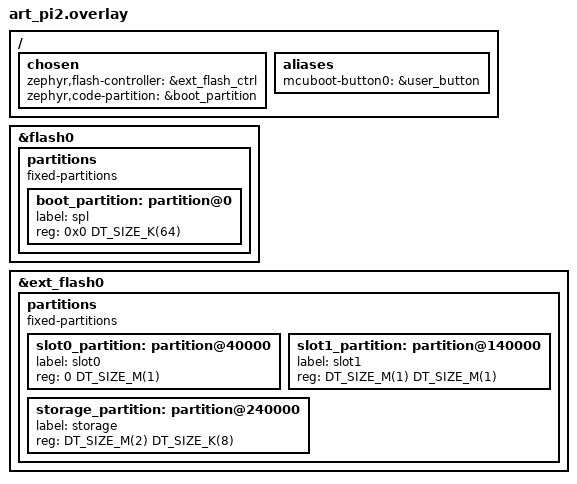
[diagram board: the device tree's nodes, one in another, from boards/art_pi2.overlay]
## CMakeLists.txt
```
# SPDX-License-Identifier: Apache-2.0

cmake_minimum_required(VERSION 3.20.0)

find_package(Zephyr REQUIRED HINTS $ENV{ZEPHYR_BASE})
project(bootloader)

target_sources(app PRIVATE
    src/main.c
    src/flash_helper.c
    ../common/ymodem.c
    src/menu.c
    ../common/firmware_loader.c
)

zephyr_include_directories(app PRIVATE_HEADER ../common)
```

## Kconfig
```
# SPDX-License-Identifier: Apache-2.0

source "Kconfig.zephyr"

config SPL_DIRECT_FLASH_WRITE
	bool "Direct Flash Write Mode (bypass RAM buffer)"
	default n
	help
	  If enabled, YModem received data is written directly to Flash
	  without using an intermediate RAM buffer. This saves RAM but
	  requires the target Flash region to be erased before reception.

	  If disabled (default), data is first received into a heap-allocated
	  RAM buffer, verified, then written to Flash.
```

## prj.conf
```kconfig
# SPDX-License-Identifier: Apache-2.0

# ========================================
# SPL (Stage 1) - 最小化配置
# ========================================

# 堆栈和堆内存配置
CONFIG_MAIN_STACK_SIZE=4096
CONFIG_HEAP_MEM_POOL_SIZE=393216

# 最小化 libc
CONFIG_MINIMAL_LIBC=y
CONFIG_STDOUT_CONSOLE=y

# 串口配置
CONFIG_SERIAL=y
CONFIG_UART_CONSOLE=y
CONFIG_UART_INTERRUPT_DRIVEN=n

# GPIO 配置
CONFIG_GPIO=y

# 内部 Flash 配置
CONFIG_FLASH=y
CONFIG_FLASH_PAGE_LAYOUT=y

# 关闭日志系统
# CONFIG_LOG is not set

# 关闭 Shell
# CONFIG_SHELL is not set

# 启动配置
CONFIG_BOOT_DELAY=0

CONFIG_INPUT=y
CONFIG_INPUT_MODE_SYNCHRONOUS=y

# CRC 支持（用于固件头校验）
CONFIG_CRC=y
CONFIG_CRC32_IEEE=y

# 关断其他不需要的功能
CONFIG_REBOOT=y

# 直接写入 Flash 模式（通过 Kconfig 启用）
# 启用后 YModem 数据不再经过 RAM 缓冲，直接写入 Flash
# 可节省 ~256KB 堆内存（TPL 场景），但要求 Flash 先擦除后写入
CONFIG_SPL_DIRECT_FLASH_WRITE=y
# CONFIG_USB_CDC_ACM=y
```

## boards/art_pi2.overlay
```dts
/ {
    chosen {
        zephyr,flash-controller = &ext_flash_ctrl;
        zephyr,code-partition = &boot_partition;
    };

    aliases {
        mcuboot-button0 = &user_button;
    };
};

&flash0 {
    partitions {
        compatible = "fixed-partitions";
        #address-cells = <1>;
        #size-cells = <1>;

        boot_partition: partition@0 {
            label = "spl";
            reg = <0x0 DT_SIZE_K(64)>;
        };
    };
};

&ext_flash0 {
    partitions {
        compatible = "fixed-partitions";
        #address-cells = <1>;
        #size-cells = <1>;

        /* 删除基础设备树中的 storage_partition */
        /delete-node/ partition@0;

        slot0_partition: partition@40000 {
            label = "slot0";
            reg = <0 DT_SIZE_M(1)>;
        };

        slot1_partition: partition@140000 {
            label = "slot1";
            reg = <DT_SIZE_M(1) DT_SIZE_M(1)>;
        };

        storage_partition: partition@240000 {
            label = "storage";
            reg = <DT_SIZE_M(2) DT_SIZE_K(8)>;
        };
    };
};
```

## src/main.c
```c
/*
 * Copyright (c) 2024
 *
 * SPDX-License-Identifier: Apache-2.0
 */

#include <string.h>
#include <zephyr/device.h>
#include <zephyr/drivers/gpio.h>
#include <zephyr/drivers/uart.h>
#include <zephyr/kernel.h>
#include <zephyr/logging/log.h>
#include <zephyr/sys/crc.h>
#include <zephyr/sys/reboot.h>

#include "firmware_loader.h"
#include "flash_helper.h"
#include "ymodem.h"

LOG_MODULE_DECLARE(spl, CONFIG_LOG_DEFAULT_LEVEL);

#define RED_LED_NODE DT_NODELABEL(red_led)
#define BLUE_LED_NODE DT_NODELABEL(blue_led)
static const struct gpio_dt_spec red_led =
    GPIO_DT_SPEC_GET_OR(RED_LED_NODE, gpios, {0});
static const struct gpio_dt_spec blue_led =
    GPIO_DT_SPEC_GET_OR(BLUE_LED_NODE, gpios, {0});
static const struct gpio_dt_spec btn0 =
    GPIO_DT_SPEC_GET(DT_ALIAS(mcuboot_button0), gpios);

struct spl_write_ctx {
  bool update_spl;
  uint32_t flash_addr;
#if !defined(CONFIG_SPL_DIRECT_FLASH_WRITE)
  uint8_t* ram_buf;
#endif
};

static void spl_init(void);
static void spl_led_init(void);
static void spl_led_set(bool red_on, bool blue_on);
static void spl_jump_to_tpl(void);
static void spl_jump_to_address(uint32_t addr);
static int spl_update_mode(bool update_spl);

int main(void) {
  int value;

  spl_init();
  gpio_pin_configure_dt(&btn0, GPIO_INPUT);

  value = gpio_pin_get_dt(&btn0);

  if (value) {
    LOG_INF("upgrading TPL");
    spl_update_mode(false);
    k_sleep(K_MSEC(1000));
    sys_reboot(SYS_REBOOT_COLD);
  }

  LOG_DBG("Checking TPL...\n");

  {
    struct firmware_header tpl_header;
    int rc;

    rc = firmware_verify_from_flash(EXT_FLASH_TPL_ADDR, &tpl_header,
                                    FW_MAGIC_TPL, flash_external_read);

    if (rc == FW_LOADER_SUCCESS) {
      LOG_DBG("TPL found at 0x%08X\n", EXT_FLASH_TPL_ADDR);
      spl_led_set(false, true); /* 蓝灯亮 */

      LOG_DBG("Jumping to TPL...\n");
      k_sleep(K_MSEC(100));

      rc = firmware_load_and_jump(&tpl_header, EXT_FLASH_TPL_ADDR,
                             flash_external_read);

      LOG_ERR("TPL jump failed (rc=%d), entering update mode...", rc);
      spl_led_set(true, true);

      if (spl_update_mode(false) == 0) {
        LOG_INF("TPL update successful, rebooting...\n");
      } else {
        LOG_ERR("TPL update failed, rebooting...\n");
      }

      k_sleep(K_MSEC(1000));
      sys_reboot(SYS_REBOOT_COLD);
    } else {
      LOG_ERR("TPL not found or invalid! (rc=%d)\n", rc);
      LOG_DBG("Entering TPL update mode...\n");
      spl_led_set(true, true);

      if (spl_update_mode(false) == 0) {
        LOG_DBG("TPL update successful, rebooting...\n");
      } else {
        LOG_ERR("TPL update failed, rebooting...\n");
      }

      k_sleep(K_MSEC(1000));
      sys_reboot(SYS_REBOOT_COLD);
    }
  }

  return 0;
}

static const struct device* g_uart_dev;

static void spl_init(void) {
  spl_led_init();
  spl_led_set(false, false);

  flash_internal_init();
  flash_external_init();

  g_uart_dev = DEVICE_DT_GET(DT_CHOSEN(zephyr_console));
  if (!device_is_ready(g_uart_dev)) {
    LOG_ERR("UART device not ready");
    while (1) {
    }
  }

  LOG_INF("SPL initialized");
}

static void spl_led_init(void) {
  if (device_is_ready(red_led.port)) {
    gpio_pin_configure_dt(&red_led, GPIO_OUTPUT);
    gpio_pin_set_dt(&red_led, 0);
  }

  if (device_is_ready(blue_led.port)) {
    gpio_pin_configure_dt(&blue_led, GPIO_OUTPUT);
    gpio_pin_set_dt(&blue_led, 0);
  }
}

static void spl_led_set(bool red_on, bool blue_on) {
  if (device_is_ready(red_led.port)) {
    gpio_pin_set_dt(&red_led, red_on ? 1 : 0);
  }

  if (device_is_ready(blue_led.port)) {
    gpio_pin_set_dt(&blue_led, blue_on ? 1 : 0);
  }
}

static int spl_block_write(uint32_t addr, const uint8_t* data, size_t len,
                           uint32_t total, int file_size, void* priv) {
  struct spl_write_ctx* ctx = (struct spl_write_ctx*)priv;

#if defined(CONFIG_SPL_DIRECT_FLASH_WRITE)
  if (ctx->update_spl) {
    return flash_internal_write(ctx->flash_addr + total - len, data, len);
  } else {
    return flash_external_write(ctx->flash_addr + total - len, data, len);
  }
#else
  memcpy(ctx->ram_buf + total - len, data, len);
  return 0;
#endif
}

static int spl_update_mode(bool update_spl) {
  struct ymodem_config config;
  struct spl_write_ctx wctx;
  struct firmware_header fw_header;
  uint32_t flash_addr;
  uint32_t max_size;
  int rc;

  if (update_spl) {
    flash_addr = FLASH_BASE_ADDR;
    max_size = SPL_FLASH_SIZE;
    LOG_INF("Send SPL firmware via YModem (max %d KB)...", max_size / 1024);
  } else {
    flash_addr = EXT_FLASH_TPL_ADDR;
    max_size = EXT_FLASH_TPL_SIZE;
    LOG_INF("Send TPL firmware via YModem (max %d KB)...", max_size / 1024);
  }

#if defined(CONFIG_SPL_DIRECT_FLASH_WRITE)
  LOG_DBG("Erasing Flash at 0x%08X (%u bytes)...", flash_addr, max_size);
  if (update_spl) {
    rc = flash_internal_erase(flash_addr, max_size);
  } else {
    rc = flash_external_erase(flash_addr, max_size);
  }
  if (rc != 0) {
    LOG_ERR("Flash erase failed (rc=%d)", rc);
    return -1;
  }
  LOG_DBG("Flash erase complete\n");

  wctx.update_spl = update_spl;
  wctx.flash_addr = flash_addr;

  config.dev = g_uart_dev;
  config.flash_addr = flash_addr;
  config.max_size = max_size;
  config.block_write_cb = spl_block_write;
  config.priv = &wctx;

  rc = ymodem_recv(&config);
  if (rc < 0) {
    LOG_ERR("YModem receive failed (%d)", rc);
    return -1;
  }
  LOG_DBG("Received %u bytes\n", rc);

  if (update_spl) {
    rc = flash_internal_read(flash_addr, (uint8_t*)&fw_header,
                             sizeof(fw_header));
  } else {
    rc = flash_external_read(flash_addr, (uint8_t*)&fw_header,
                             sizeof(fw_header));
  }
  if (rc != 0) {
    LOG_ERR("Failed to read firmware header from Flash (rc=%d)", rc);
    return -1;
  }

  rc = firmware_header_verify(&fw_header,
                              update_spl ? FW_MAGIC_SPL : FW_MAGIC_TPL);
  if (rc != FW_LOADER_SUCCESS) {
    LOG_ERR("Firmware header verification failed (rc=%d)", rc);
    return -1;
  }
  LOG_INF("Firmware header verified OK");

  {
    uint32_t payload_size = fw_header.firmware_size - FIRMWARE_HEADER_SIZE;

    if (payload_size > 0 && payload_size <= max_size) {
      uint32_t calc_crc = 0xFFFFFFFF;
      uint32_t offset = FIRMWARE_HEADER_SIZE;
      uint32_t remaining = payload_size;
      uint8_t chunk_buf[256];

      while (remaining > 0) {
        uint32_t chunk =
            (remaining > sizeof(chunk_buf)) ? sizeof(chunk_buf) : remaining;

        if (update_spl) {
          rc = flash_internal_read(flash_addr + offset, chunk_buf, chunk);
        } else {
          rc = flash_external_read(flash_addr + offset, chunk_buf, chunk);
        }
        if (rc != 0) {
          LOG_ERR("Failed to read payload from Flash at "
                  "offset 0x%X (rc=%d)",
                  offset, rc);
          return -1;
        }
        calc_crc = crc32_ieee_update(calc_crc, chunk_buf, chunk);
        offset += chunk;
        remaining -= chunk;
      }

      calc_crc ^= 0xFFFFFFFF;

      if (calc_crc == fw_header.checksum) {
        LOG_INF("Firmware checksum verified OK (0x%08X)", fw_header.checksum);
      } else {
        LOG_ERR("Firmware checksum verification failed "
                "(calc 0x%08X, stored 0x%08X)",
                calc_crc, fw_header.checksum);
      }
      LOG_INF("Firmware verified successfully (%u bytes payload)",
              payload_size);
    }
  }

#else
  uint8_t* ram_buf = k_malloc(max_size);
  if (!ram_buf) {
    LOG_ERR("RAM buffer allocation failed");
    return -1;
  }
  LOG_INF("Using RAM buffer at 0x%08X for firmware reception\n",
          (uint32_t)ram_buf);
  memset(ram_buf, 0, max_size);

  wctx.update_spl = update_spl;
  wctx.flash_addr = flash_addr;
  wctx.ram_buf = ram_buf;

  config.dev = g_uart_dev;
  config.flash_addr = (uint32_t)ram_buf;
  config.max_size = max_size;
  config.block_write_cb = spl_block_write;
  config.priv = &wctx;

  rc = ymodem_recv(&config);
  if (rc < 0) {
    LOG_ERR("YModem receive failed (%d)", rc);
    k_free(ram_buf);
    return -1;
  }
  LOG_DBG("Received %u bytes\n", rc);

  {
    const struct firmware_header* fw_header;
    int vrc;

    fw_header = (const struct firmware_header*)ram_buf;
    vrc = firmware_header_verify(fw_header,
                                 update_spl ? FW_MAGIC_SPL : FW_MAGIC_TPL);
    if (vrc != FW_LOADER_SUCCESS) {
      LOG_ERR("Firmware header verification failed (rc=%d)", vrc);
      k_free(ram_buf);
      return -1;
    }
    LOG_INF("Firmware header verified OK");

    {
      uint32_t payload_size = fw_header->firmware_size - FIRMWARE_HEADER_SIZE;
      const uint8_t* payload = (const uint8_t*)fw_header + FIRMWARE_HEADER_SIZE;

      if (payload_size > 0 && payload_size <= max_size) {
        vrc = firmware_verify_checksum(fw_header, payload);
        if (vrc == FW_LOADER_SUCCESS) {
          LOG_INF("Firmware checksum verified OK (0x%08X)",
                  fw_header->checksum);
        } else {
          LOG_ERR("Warning: Firmware checksum verification "
                  "failed (rc=%d)",
                  vrc);
        }
        LOG_INF("Firmware verified successfully (%u bytes payload)",
                payload_size);
      }
    }
  }

  {
    uint32_t write_size = (uint32_t)rc;

    LOG_DBG("Writing %u bytes to Flash at 0x%08X...", write_size, flash_addr);

    if (update_spl) {
      rc = flash_internal_erase(flash_addr, write_size);
    } else {
      rc = flash_external_erase(flash_addr, write_size);
    }
    if (rc != 0) {
      LOG_ERR("Flash erase failed (rc=%d)", rc);
      k_free(ram_buf);
      return -1;
    }

    {
      uint32_t offset = 0;
      const uint32_t chunk_size = 256;

      while (offset < write_size) {
        uint32_t chunk = (write_size - offset > chunk_size)
                             ? chunk_size
                             : (write_size - offset);

        if (update_spl) {
          rc = flash_internal_write(flash_addr + offset, ram_buf + offset,
                                    chunk);
        } else {
          rc = flash_external_write(flash_addr + offset, ram_buf + offset,
                                    chunk);
        }
        if (rc != 0) {
          LOG_ERR("Flash write failed at offset 0x%X (rc=%d)", offset, rc);
          k_free(ram_buf);
          return -1;
        }
        offset += chunk;
      }
    }
    LOG_DBG("Flash write complete\n");
    k_free(ram_buf);
  }
#endif

  return 0;
}

static void spl_jump_to_tpl(void) { spl_jump_to_address(EXT_FLASH_TPL_ADDR); }

static void spl_jump_to_address(uint32_t addr) {
  uint32_t* vector_table = (uint32_t*)addr;
  uint32_t stack_ptr;
  uint32_t reset_handler;
  void (*jump_to_app)(void);

  __disable_irq();

  SysTick->CTRL = 0;
  SysTick->VAL = 0;

  SCB->VTOR = addr;

  stack_ptr = vector_table[0];
  reset_handler = vector_table[1];

  if (!((stack_ptr >= 0x20000000 && stack_ptr <= 0x20050000) ||
        (stack_ptr >= 0x24000000 && stack_ptr <= 0x24080000))) {
    LOG_ERR("Error: Invalid stack pointer: 0x%08X", stack_ptr);
    return;
  }

  if (reset_handler < addr || reset_handler > addr + 0x100000) {
    LOG_ERR("Error: Invalid reset handler: 0x%08X", reset_handler);
    return;
  }

  __set_MSP(stack_ptr);

  for (int i = 0; i < 8; i++) {
    NVIC->ICER[i] = 0xFFFFFFFF;
  }

  jump_to_app = (void (*)(void))reset_handler;
  jump_to_app();
}
```

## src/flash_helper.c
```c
/*
 * Copyright (c) 2024
 *
 * SPDX-License-Identifier: Apache-2.0
 */


#include <zephyr/sys/printk.h>
#include <zephyr/logging/log.h>
#include <string.h>

#include "flash_helper.h"

LOG_MODULE_DECLARE(flash, CONFIG_LOG_DEFAULT_LEVEL);

static const struct device *flash_internal_dev = NULL;
static const struct device *flash_external_dev = NULL;

static const uint16_t crc16_table[256] = {
    0x0000, 0x1021, 0x2042, 0x3063, 0x4084, 0x50A5, 0x60C6, 0x70E7,
    0x8108, 0x9129, 0xA14A, 0xB16B, 0xC18C, 0xD1AD, 0xE1CE, 0xF1EF,
    0x1231, 0x0210, 0x3273, 0x2252, 0x52B5, 0x4294, 0x72F7, 0x62D6,
    0x9339, 0x8318, 0xB37B, 0xA35A, 0xD3BD, 0xC39C, 0xF3FF, 0xE3DE,
    0x2462, 0x3443, 0x0420, 0x1401, 0x64E6, 0x74C7, 0x44A4, 0x5485,
    0xA56A, 0xB54B, 0x8528, 0x9509, 0xE5EE, 0xF5CF, 0xC5AC, 0xD58D,
    0x3653, 0x2672, 0x1611, 0x0630, 0x76D7, 0x66F6, 0x5695, 0x46B4,
    0xB75B, 0xA77A, 0x9719, 0x8738, 0xF7DF, 0xE7FE, 0xD79D, 0xC7BC,
    0x48C4, 0x58E5, 0x6886, 0x78A7, 0x0840, 0x1861, 0x2802, 0x3823,
    0xC9CC, 0xD9ED, 0xE98E, 0xF9AF, 0x8948, 0x9969, 0xA90A, 0xB92B,
    0x5AF5, 0x4AD4, 0x7AB7, 0x6A96, 0x1A71, 0x0A50, 0x3A33, 0x2A12,
    0xDBFD, 0xCBDC, 0xFBBF, 0xEB9E, 0x9B79, 0x8B58, 0xBB3B, 0xAB1A,
    0x6CA6, 0x7C87, 0x4CE4, 0x5CC5, 0x2C22, 0x3C03, 0x0C60, 0x1C41,
    0xEDAE, 0xFD8F, 0xCDEC, 0xDDCD, 0xAD2A, 0xBD0B, 0x8D68, 0x9D49,
    0x7E97, 0x6EB6, 0x5ED5, 0x4EF4, 0x3E13, 0x2E32, 0x1E51, 0x0E70,
    0xFF9F, 0xEFBE, 0xDFDD, 0xCFFC, 0xBF1B, 0xAF3A, 0x9F59, 0x8F78,
    0x9188, 0x81A9, 0xB1CA, 0xA1EB, 0xD10C, 0xC12D, 0xF14E, 0xE16F,
    0x1080, 0x00A1, 0x30C2, 0x20E3, 0x5004, 0x4025, 0x7046, 0x6067,
    0x83B9, 0x9398, 0xA3FB, 0xB3DA, 0xC33D, 0xD31C, 0xE37F, 0xF35E,
    0x02B1, 0x1290, 0x22F3, 0x32D2, 0x4235, 0x5214, 0x6277, 0x7256,
    0xB5EA, 0xA5CB, 0x95A8, 0x8589, 0xF56E, 0xE54F, 0xD52C, 0xC50D,
    0x34E2, 0x24C3, 0x14A0, 0x0481, 0x7466, 0x6447, 0x5424, 0x4405,
    0xA7DB, 0xB7FA, 0x8799, 0x97B8, 0xE75F, 0xF77E, 0xC71D, 0xD73C,
    0x26D3, 0x36F2, 0x0691, 0x16B0, 0x6657, 0x7676, 0x4615, 0x5634,
    0xD94C, 0xC96D, 0xF90E, 0xE92F, 0x99C8, 0x89E9, 0xB98A, 0xA9AB,
    0x5844, 0x4865, 0x7806, 0x6827, 0x18C0, 0x08E1, 0x3882, 0x28A3,
    0xCB7D, 0xDB5C, 0xEB3F, 0xFB1E, 0x8BF9, 0x9BD8, 0xABBB, 0xBB9A,
    0x4A75, 0x5A54, 0x6A37, 0x7A16, 0x0AF1, 0x1AD0, 0x2AB3, 0x3A92,
    0xFD2E, 0xED0F, 0xDD6C, 0xCD4D, 0xBDAA, 0xAD8B, 0x9DE8, 0x8DC9,
    0x7C26, 0x6C07, 0x5C64, 0x4C45, 0x3CA2, 0x2C83, 0x1CE0, 0x0CC1,
    0xEF1F, 0xFF3E, 0xCF5D, 0xDF7C, 0xAF9B, 0xBFBA, 0x8FD9, 0x9FF8,
    0x6E17, 0x7E36, 0x4E55, 0x5E74, 0x2E93, 0x3EB2, 0x0ED1, 0x1EF0
};

int flash_internal_init(void)
{
    flash_internal_dev = DEVICE_DT_GET(DT_NODELABEL(flash));
    
    if (!device_is_ready(flash_internal_dev)) {
        LOG_ERR("Internal flash device not ready");
        return FLASH_OP_ERROR;
    }
    
    return FLASH_OP_SUCCESS;
}

int flash_external_init(void)
{
    flash_external_dev = DEVICE_DT_GET(DT_NODELABEL(ext_flash_ctrl));
    
    if (!device_is_ready(flash_external_dev)) {
        LOG_ERR("External flash device not ready");
        return FLASH_OP_ERROR;
    }
    
    return FLASH_OP_SUCCESS;
}

int flash_internal_erase(uint32_t addr, size_t len)
{
    struct flash_pages_info page_info;
    off_t offset, end_offset;
    int rc;
    
    if (flash_internal_dev == NULL) {
        if (flash_internal_init() != FLASH_OP_SUCCESS) {
            LOG_ERR("Internal flash init err");
            return FLASH_OP_ERROR;
        }
    }
    
    if (addr < FLASH_BASE_ADDR || (addr + len) > (FLASH_BASE_ADDR + SPL_FLASH_SIZE)) {
        LOG_ERR("Invalid internal flash address range");
        return FLASH_OP_ERROR;
    }
    
    offset = addr - FLASH_BASE_ADDR;
    end_offset = offset + len;
    
    while (offset < end_offset) {
        rc = flash_get_page_info_by_offs(flash_internal_dev, offset, &page_info);
        if (rc != 0) {
            LOG_ERR("Failed to get page info at offset 0x%lx", (long)offset);
            return FLASH_OP_ERROR;
        }
        
        rc = flash_erase(flash_internal_dev, page_info.start_offset, page_info.size);
        if (rc != 0) {
            LOG_ERR("Flash erase failed (rc=%d) at offset 0x%lx", rc, (long)page_info.start_offset);
            return FLASH_OP_ERROR;
        }

        offset = page_info.start_offset + page_info.size;
    }
    
    return FLASH_OP_SUCCESS;
}

int flash_internal_write(uint32_t addr, const uint8_t *data, size_t len)
{
    off_t offset;
    int rc;
    
    if (flash_internal_dev == NULL) {
        if (flash_internal_init() != FLASH_OP_SUCCESS) {
            LOG_ERR("Internal flash init err");
            return FLASH_OP_ERROR;
        }
    }
    
    if (addr < FLASH_BASE_ADDR || (addr + len) > (FLASH_BASE_ADDR + SPL_FLASH_SIZE)) {
        LOG_ERR("Invalid internal flash address range");
        return FLASH_OP_ERROR;
    }
    
    if ((addr & 0x3) != 0) {
        LOG_ERR("Flash write address must be 4-byte aligned");
        return FLASH_OP_ERROR;
    }

    offset = addr - FLASH_BASE_ADDR;
    
    rc = flash_write(flash_internal_dev, offset, data, len);
    if (rc != 0) {
        LOG_ERR("Flash write failed (rc=%d)\n", rc);
        return FLASH_OP_ERROR;
    }
    
    return FLASH_OP_SUCCESS;
}

int flash_internal_read(uint32_t addr, uint8_t *data, size_t len)
{
    off_t offset;
    int rc;
    
    if (flash_internal_dev == NULL) {
        if (flash_internal_init() != FLASH_OP_SUCCESS) {
            LOG_ERR("Internal flash init err");
            return FLASH_OP_ERROR;
        }
    }
    
    if (addr < FLASH_BASE_ADDR || (addr + len) > (FLASH_BASE_ADDR + SPL_FLASH_SIZE)) {
        LOG_ERR("Invalid internal flash address range");
        return FLASH_OP_ERROR;
    }
    
    offset = addr - FLASH_BASE_ADDR;
    
    rc = flash_read(flash_internal_dev, offset, data, len);
    if (rc != 0) {
        LOG_ERR("Flash read failed (rc=%d)", rc);
        return FLASH_OP_ERROR;
    }
    
    return FLASH_OP_SUCCESS;
}

int flash_external_erase(uint32_t addr, size_t len)
{
    struct flash_pages_info page_info;
    off_t offset, end_offset;
    int rc;
    
    if (flash_external_dev == NULL) {
        if (flash_external_init() != FLASH_OP_SUCCESS) {
            LOG_ERR("external flash init err");
            return FLASH_OP_ERROR;
        }
    }

    offset = addr - EXT_FLASH_BASE_ADDR;
    end_offset = offset + len;

    while (offset < end_offset) {
        rc = flash_get_page_info_by_offs(flash_external_dev, offset, &page_info);
        if (rc != 0) {
            LOG_ERR("Failed to get page info at offset 0x%lx", (long)offset);
            return FLASH_OP_ERROR;
        }
        
        rc = flash_erase(flash_external_dev, page_info.start_offset, page_info.size);
        if (rc != 0) {
            LOG_ERR("External flash erase failed (rc=%d) at offset 0x%lx", rc, (long)page_info.start_offset);
            return FLASH_OP_ERROR;
        }

        offset = page_info.start_offset + page_info.size;
    }
    
    return FLASH_OP_SUCCESS;
}

int flash_external_write(uint32_t addr, const uint8_t *data, size_t len)
{
    off_t offset;
    int rc;
    
    if (flash_external_dev == NULL) {
        if (flash_external_init() != FLASH_OP_SUCCESS) {
            LOG_ERR("External flash init err");
            return FLASH_OP_ERROR;
        }
    }
    
    if ((addr & 0x3) != 0) {
        LOG_ERR("Flash write address must be 4-byte aligned");
        return FLASH_OP_ERROR;
    }
    
    offset = addr - EXT_FLASH_BASE_ADDR;

    rc = flash_write(flash_external_dev, offset, data, len);
    if (rc != 0) {
        LOG_ERR("External flash write failed (rc=%d)", rc);
        return FLASH_OP_ERROR;
    }
    
    return FLASH_OP_SUCCESS;
}

int flash_external_read(uint32_t addr, uint8_t *data, size_t len)
{
    off_t offset;
    int rc;
    
    if (flash_external_dev == NULL) {
        if (flash_external_init() != FLASH_OP_SUCCESS) {
            LOG_ERR("External flash init err");
            return FLASH_OP_ERROR;
        }
    }

    offset = addr - EXT_FLASH_BASE_ADDR;

    rc = flash_read(flash_external_dev, offset, data, len);
    if (rc != 0) {
        LOG_ERR("Error: External flash read failed (rc=%d)", rc);
        return FLASH_OP_ERROR;
    }
    
    return FLASH_OP_SUCCESS;
}

bool flash_verify_magic(uint32_t addr, uint32_t magic)
{
    uint32_t value;
    int rc;
    
    if ((addr & 0x3) != 0) {
        return false;
    }
    
    /* 对于外部 Flash 地址，使用 flash_read API 而不是直接指针访问
     * 原因：flash_external_erase() 后 XSPI 可能退出 Memory Map 模式，
     * 直接指针访问会导致 Bus Fault
     */
    if (addr >= EXT_FLASH_BASE_ADDR && flash_external_dev != NULL) {
        rc = flash_read(flash_external_dev, addr - EXT_FLASH_BASE_ADDR, &value, sizeof(value));
        if (rc != 0) {
            return false;
        }
    } else if (addr >= FLASH_BASE_ADDR && flash_internal_dev != NULL) {
        rc = flash_read(flash_internal_dev, addr - FLASH_BASE_ADDR, &value, sizeof(value));
        if (rc != 0) {
            return false;
        }
    } else {
        /* 回退到直接指针访问 */
        uint32_t *ptr = (uint32_t *)addr;
        value = *ptr;
    }
    
    return (value == magic);
}

uint16_t flash_calc_crc16(const uint8_t *data, size_t len)
{
    uint16_t crc = 0xFFFF;
    
    while (len--) {
        crc = (crc << 8) ^ crc16_table[((crc >> 8) ^ *data++) & 0xFF];
    }
    
    return crc;
}

bool flash_verify_crc(uint32_t addr, size_t len, uint16_t expected_crc)
{
    uint16_t calc_crc;
    
    /* 直接从内存映射读取 */
    const uint8_t *data = (const uint8_t *)addr;
    
    calc_crc = flash_calc_crc16(data, len);
    
    return (calc_crc == expected_crc);
}
```

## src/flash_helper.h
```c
/*
 * Copyright (c) 2024
 *
 * SPDX-License-Identifier: Apache-2.0
 */

#ifndef FLASH_HELPER_H
#define FLASH_HELPER_H

#include <zephyr/kernel.h>
#include <zephyr/device.h>
#include <zephyr/devicetree.h>
#include <zephyr/drivers/flash.h>
#include <zephyr/storage/flash_map.h>

#define FLASH_BASE_ADDR            0x08000000
#define SPL_FLASH_SIZE             (64 * 1024)

#define EXT_FLASH_BASE_ADDR        0x70000000
#define EXT_FLASH_TPL_ADDR         0x70000000
#define EXT_FLASH_TPL_SIZE         (256 * 1024)
#define EXT_FLASH_SLOT0_ADDR       0x70040000
#define EXT_FLASH_SLOT0_SIZE       (1 * 1024 * 1024)
#define EXT_FLASH_SLOT1_ADDR       0x70140000
#define EXT_FLASH_SLOT1_SIZE       (1 * 1024 * 1024)

#define SPL_MAGIC                  0x53504C53
#define TPL_MAGIC                  0x54504C54
#define APP_MAGIC                  0x41505041

#define FLASH_OP_SUCCESS           0
#define FLASH_OP_ERROR             -1
#define FLASH_OP_VERIFY_ERROR      -2
#define FLASH_OP_TIMEOUT           -3

int flash_internal_init(void);
int flash_external_init(void);
int flash_internal_erase(uint32_t addr, size_t len);
int flash_internal_write(uint32_t addr, const uint8_t *data, size_t len);
int flash_internal_read(uint32_t addr, uint8_t *data, size_t len);
int flash_external_erase(uint32_t addr, size_t len);
int flash_external_write(uint32_t addr, const uint8_t *data, size_t len);
int flash_external_read(uint32_t addr, uint8_t *data, size_t len);
bool flash_verify_magic(uint32_t addr, uint32_t magic);
uint16_t flash_calc_crc16(const uint8_t *data, size_t len);
bool flash_verify_crc(uint32_t addr, size_t len, uint16_t expected_crc);

#endif /* FLASH_HELPER_H */
```

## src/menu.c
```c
/*
 * Copyright (c) 2024
 *
 * SPDX-License-Identifier: Apache-2.0
 */

#include "menu.h"
#include <zephyr/kernel.h>
#include <zephyr/sys/printk.h>
#include <zephyr/device.h>
#include <zephyr/devicetree.h>
#include <zephyr/drivers/uart.h>

enum input_state {
    STATE_NORMAL,
    STATE_ESC,
    STATE_ESC_BRACKET,
};

struct menu_item {
    const char *name;
    int id;
};

static const struct menu_item menu_items[] = {
    {"Normal Boot", NORMAL_BOOT},
    {"Update SPL Firmware", UPGRADE_SPL},
    {"Update TPL Firmware", UPGRADE_TPL},
    {"Update Application", UPGRADE_APP},
};

static void draw_menu(int selection, uint32_t remaining)
{
    printk("\033[5;0H");
    printk("\033[K");
    printk("Boot Menu (Auto-select in %us):\n\n", remaining);

    for (int i = 0; i < MENU_ITEM_COUNT; i++) {
        if (i == selection) {
            printk(ANSI_REVERSE "  [*] %s" ANSI_RESET "\n", menu_items[i].name);
        } else {
            printk("  [ ] %s\n", menu_items[i].name);
        }
    }

    printk("\nUse ↑↓ to select, Enter to confirm");
}

int show_menu(uint32_t timeout)
{
    const struct device *uart_dev;
    int selection = 0;
    enum input_state state = STATE_NORMAL;
    uint64_t start_time;
    uint64_t elapsed;
    uint32_t last_remaining = 0xFFFFFFFF;
    bool timeout_enabled = true;
    unsigned char c;
    int rc;
    
    uart_dev = DEVICE_DT_GET(DT_CHOSEN(zephyr_console));
    if (!device_is_ready(uart_dev)) {
        printk("Error: UART device not ready\n");
        return NORMAL_BOOT;
    }

    printk(ANSI_CLEAR);
    printk(ANSI_HOME);

    printk("========================================\n");
    printk("  ART-Pi2 SPL (Stage 1) Bootloader\n");
    printk("========================================\n\n");
    
    printk(ANSI_SAVE_CURSOR);

    start_time = k_uptime_get();

    while (1) {
        elapsed = k_uptime_get() - start_time;
        if (timeout_enabled && elapsed >= timeout) {
            printk("\n\nTimeout - Auto-selecting Normal Boot...\n");
            return NORMAL_BOOT;
        }
        
        uint32_t remaining = timeout_enabled ? (timeout - elapsed) / 1000 : 0;
        
        if (timeout_enabled && remaining != last_remaining) {
            printk(ANSI_RESTORE_CURSOR);
            draw_menu(selection, remaining);
            last_remaining = remaining;
        } else if (!timeout_enabled && last_remaining != 0) {
            printk(ANSI_RESTORE_CURSOR);
            draw_menu(selection, 0);
            last_remaining = 0;
        }
        
        rc = uart_poll_in(uart_dev, &c);
        
        if (rc == 0) {
            switch (state) {
            case STATE_NORMAL:
                if (c == 0x1B) {
                    state = STATE_ESC;
                    timeout_enabled = false;
                } else if (c == '\r' || c == '\n') {
                    printk("\n\nSelected: %s\n", menu_items[selection].name);
                    return menu_items[selection].id;
                } else if (c >= '1' && c <= '4') {
                    int idx = c - '1';
                    if (idx < MENU_ITEM_COUNT) {
                        selection = idx;
                        printk(ANSI_RESTORE_CURSOR);
                        draw_menu(selection, remaining);
                        printk("\n\nSelected: %s\n", menu_items[selection].name);
                        return menu_items[selection].id;
                    }
                } else {
                    timeout_enabled = false;
                }
                break;
                
            case STATE_ESC:
                if (c == '[' || c == 'O') {
                    state = STATE_ESC_BRACKET;
                } else {
                    state = STATE_NORMAL;
                }
                break;
                
            case STATE_ESC_BRACKET:
                if (c == 'A') {
                    selection = (selection > 0) ? selection - 1 : MENU_ITEM_COUNT - 1;
                    printk(ANSI_RESTORE_CURSOR);
                    draw_menu(selection, remaining);
                } else if (c == 'B') {
                    selection = (selection < MENU_ITEM_COUNT - 1) ? selection + 1 : 0;
                    printk(ANSI_RESTORE_CURSOR);
                    draw_menu(selection, remaining);
                }
                state = STATE_NORMAL;
                break;
            }
        }
    }
    return NORMAL_BOOT;
}
```

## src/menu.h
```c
/*
 * Copyright (c) 2024
 *
 * SPDX-License-Identifier: Apache-2.0
 */

#ifndef MENU_H
#define MENU_H

#include <stdint.h>

#define NORMAL_BOOT 0
#define UPGRADE_SPL 1
#define UPGRADE_TPL 2
#define UPGRADE_APP 3
#define ANSI_CLEAR          "\033[2J"
#define ANSI_HOME           "\033[H"
#define ANSI_SAVE_CURSOR    "\033[s"
#define ANSI_RESTORE_CURSOR "\033[u"
#define ANSI_REVERSE        "\033[7m"
#define ANSI_RESET          "\033[0m"
#define MENU_ITEM_COUNT  4

int show_menu(uint32_t timeout);

#endif /* MENU_H */
```
